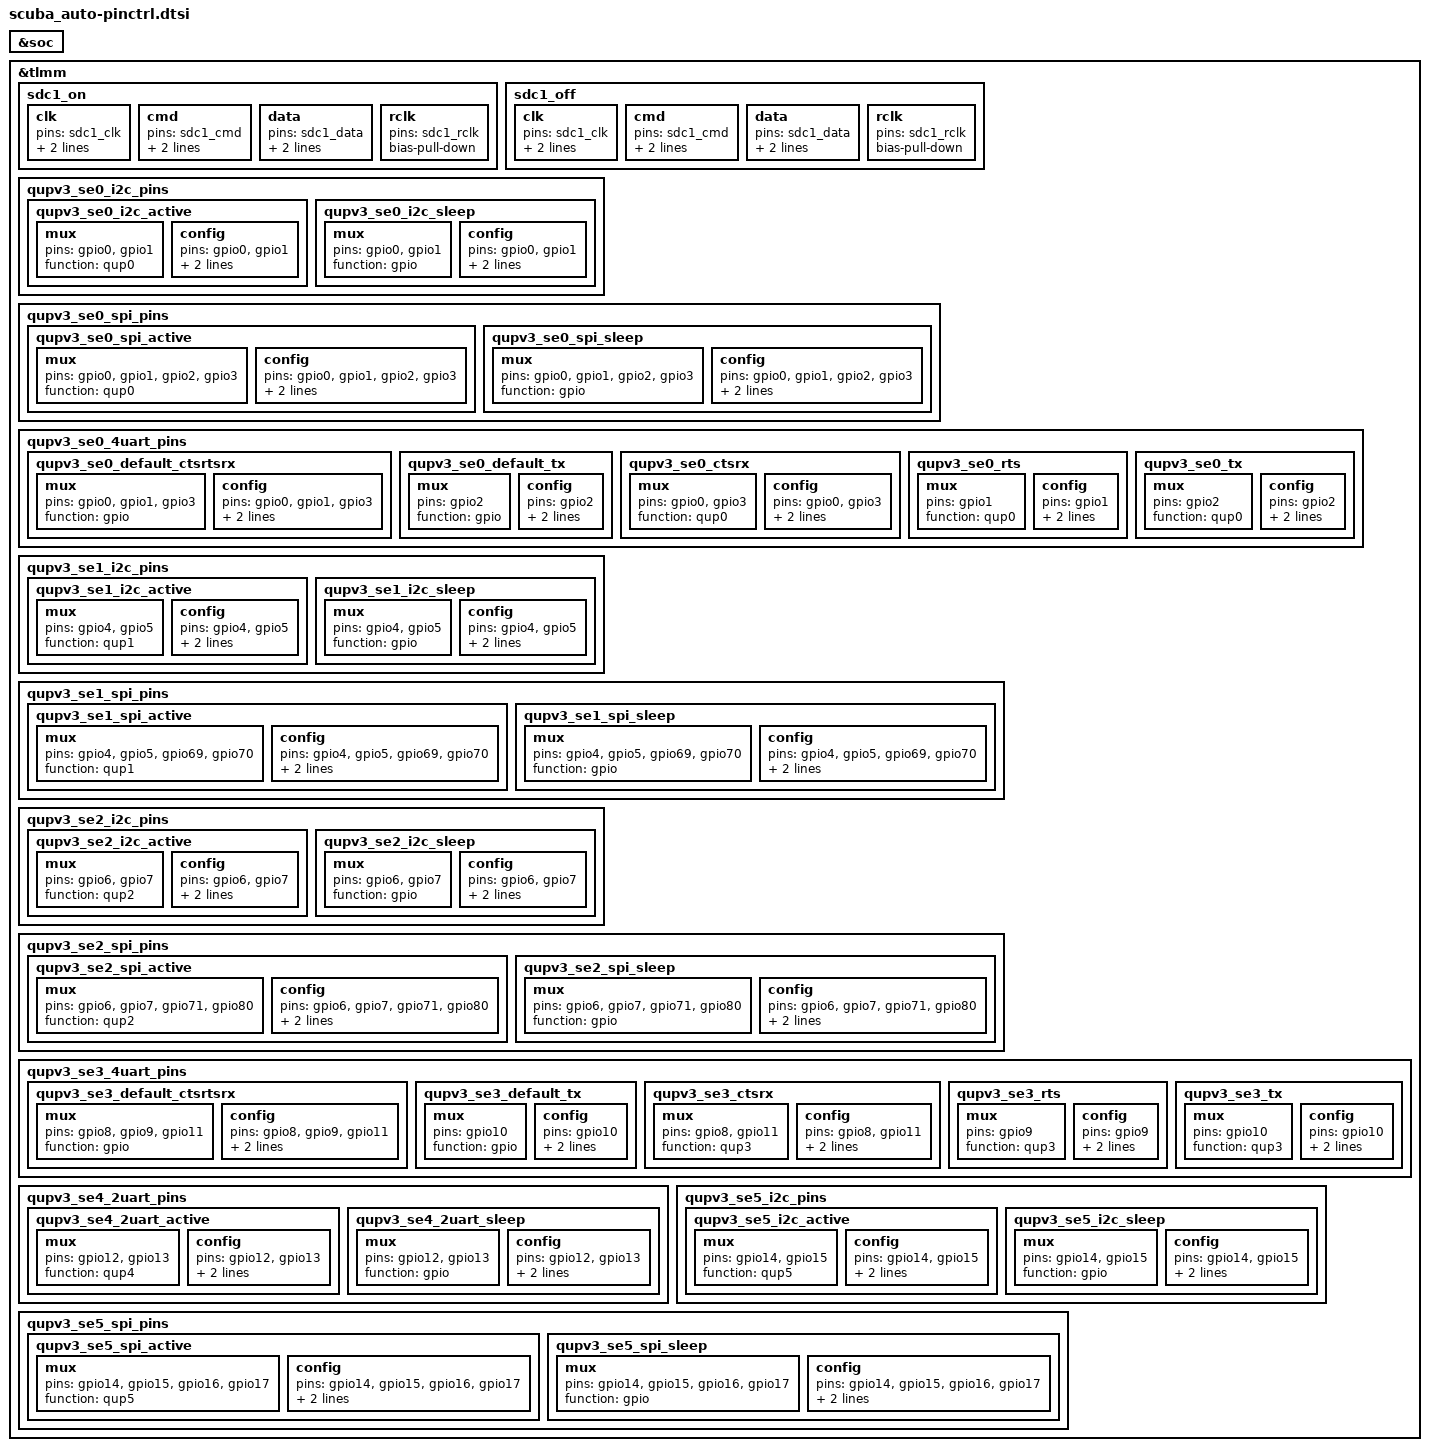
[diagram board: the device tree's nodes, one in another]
&soc { } ;
&tlmm {
	/* SDC pin type */
	sdc1_on: sdc1_on {
		clk {
			pins = "sdc1_clk";
			bias-disable;
			drive-strength = <16>;
		};

		cmd {
			pins = "sdc1_cmd";
			bias-pull-up;
			drive-strength = <10>;
		};

		data {
			pins = "sdc1_data";
			bias-pull-up;
			drive-strength = <10>;
		};

		rclk {
			pins = "sdc1_rclk";
			bias-pull-down;
		};
	};

	sdc1_off: sdc1_off {
		clk {
			pins = "sdc1_clk";
			bias-disable;
			drive-strength = <2>;
		};

		cmd {
			pins = "sdc1_cmd";
			bias-pull-up;
			drive-strength = <2>;
		};

		data {
			pins = "sdc1_data";
			bias-pull-up;
			drive-strength = <2>;
		};

		rclk {
			pins = "sdc1_rclk";
			bias-pull-down;
		};
	};

	qupv3_se0_i2c_pins: qupv3_se0_i2c_pins {
		qupv3_se0_i2c_active: qupv3_se0_i2c_active {
			mux {
				pins = "gpio0", "gpio1";
				function = "qup0";
			};

			config {
				pins = "gpio0", "gpio1";
				drive-strength = <2>;
				bias-pull-up;
			};
		};

		qupv3_se0_i2c_sleep: qupv3_se0_i2c_sleep {
			mux {
				pins = "gpio0", "gpio1";
				function = "gpio";
			};

			config {
				pins = "gpio0", "gpio1";
				drive-strength = <2>;
				bias-disable;
			};
		};
	};

	qupv3_se0_spi_pins: qupv3_se0_spi_pins {
		qupv3_se0_spi_active: qupv3_se0_spi_active {
			mux {
				pins = "gpio0", "gpio1",
						"gpio2", "gpio3";
				function = "qup0";
			};

			config {
				pins = "gpio0", "gpio1",
					"gpio2", "gpio3";
				drive-strength = <6>;
				bias-disable;
			};
		};

		qupv3_se0_spi_sleep: qupv3_se0_spi_sleep {
			mux {
				pins = "gpio0", "gpio1",
						"gpio2", "gpio3";
				function = "gpio";
			};

			config {
				pins = "gpio0", "gpio1",
						"gpio2", "gpio3";
				drive-strength = <6>;
				bias-disable;
			};
		};
	};

	qupv3_se0_4uart_pins: qupv3_se0_4uart_pins {
		qupv3_se0_default_ctsrtsrx:
			qupv3_se0_default_ctsrtsrx {
			mux {
				pins = "gpio0", "gpio1", "gpio3";
				function = "gpio";
			};

			config {
				pins = "gpio0", "gpio1", "gpio3";
				drive-strength = <2>;
				bias-pull-down;
			};
		};

		qupv3_se0_default_tx:
			qupv3_se0_default_tx {
			mux {
				pins = "gpio2";
				function = "gpio";
			};

			config {
				pins = "gpio2";
				drive-strength = <2>;
				bias-pull-up;
			};
		};

		qupv3_se0_ctsrx: qupv3_se0_ctsrx {
			mux {
				pins = "gpio0", "gpio3";
				function = "qup0";
			};

			config {
				pins = "gpio0", "gpio3";
				drive-strength = <2>;
				bias-disable;
			};
		};

		qupv3_se0_rts: qupv3_se0_rts {
			mux {
				pins = "gpio1";
				function = "qup0";
			};

			config {
				pins = "gpio1";
				drive-strength = <2>;
				bias-pull-down;
			};
		};

		qupv3_se0_tx: qupv3_se0_tx {
			mux {
				pins = "gpio2";
				function = "qup0";
			};

			config {
				pins = "gpio2";
				drive-strength = <2>;
				bias-pull-up;
			};
		};
	};

	qupv3_se1_i2c_pins: qupv3_se1_i2c_pins {
		qupv3_se1_i2c_active: qupv3_se1_i2c_active {
			mux {
				pins = "gpio4", "gpio5";
				function = "qup1";
			};

			config {
				pins = "gpio4", "gpio5";
				drive-strength = <2>;
				bias-pull-up;
			};
		};

		qupv3_se1_i2c_sleep: qupv3_se1_i2c_sleep {
			mux {
				pins = "gpio4", "gpio5";
				function = "gpio";
			};

			config {
				pins = "gpio4", "gpio5";
				drive-strength = <2>;
				bias-disable;
			};
		};
	};

	qupv3_se1_spi_pins: qupv3_se1_spi_pins {
		qupv3_se1_spi_active: qupv3_se1_spi_active {
			mux {
				pins = "gpio4", "gpio5",
						"gpio69", "gpio70";
				function = "qup1";
			};

			config {
				pins = "gpio4", "gpio5",
						"gpio69", "gpio70";
				drive-strength = <6>;
				bias-disable;
			};
		};

		qupv3_se1_spi_sleep: qupv3_se1_spi_sleep {
			mux {
				pins = "gpio4", "gpio5",
						"gpio69", "gpio70";
				function = "gpio";
			};

			config {
				pins = "gpio4", "gpio5",
						"gpio69", "gpio70";
				drive-strength = <6>;
				bias-disable;
			};
		};
	};

	qupv3_se2_i2c_pins: qupv3_se2_i2c_pins {
		qupv3_se2_i2c_active: qupv3_se2_i2c_active {
			mux {
				pins = "gpio6", "gpio7";
				function = "qup2";
			};

			config {
				pins = "gpio6", "gpio7";
				drive-strength = <2>;
				bias-pull-up;
			};
		};

		qupv3_se2_i2c_sleep: qupv3_se2_i2c_sleep {
			mux {
				pins = "gpio6", "gpio7";
				function = "gpio";
			};

			config {
				pins = "gpio6", "gpio7";
				drive-strength = <2>;
				bias-disable;
			};
		};
	};

	qupv3_se2_spi_pins: qupv3_se2_spi_pins {
		qupv3_se2_spi_active: qupv3_se2_spi_active {
			mux {
				pins = "gpio6", "gpio7",
						"gpio71", "gpio80";
				function = "qup2";
			};

			config {
				pins = "gpio6", "gpio7",
						"gpio71", "gpio80";
				drive-strength = <6>;
				bias-disable;
			};
		};

		qupv3_se2_spi_sleep: qupv3_se2_spi_sleep {
			mux {
				pins = "gpio6", "gpio7",
						"gpio71", "gpio80";
				function = "gpio";
			};

			config {
				pins = "gpio6", "gpio7",
						"gpio71", "gpio80";
				drive-strength = <6>;
				bias-disable;
			};
		};
	};

	qupv3_se3_4uart_pins: qupv3_se3_4uart_pins {
		qupv3_se3_default_ctsrtsrx:
			qupv3_se3_default_ctsrtsrx {
			mux {
				pins = "gpio8", "gpio9", "gpio11";
				function = "gpio";
			};

			config {
				pins = "gpio8", "gpio9", "gpio11";
				drive-strength = <2>;
				bias-pull-down;
			};
		};

		qupv3_se3_default_tx:
			qupv3_se3_default_tx {
			mux {
				pins = "gpio10";
				function = "gpio";
			};

			config {
				pins = "gpio10";
				drive-strength = <2>;
				bias-pull-up;
			};
		};

		qupv3_se3_ctsrx: qupv3_se3_ctsrx {
			mux {
				pins = "gpio8", "gpio11";
				function = "qup3";
			};

			config {
				pins = "gpio8", "gpio11";
				drive-strength = <2>;
				bias-disable;
			};
		};

		qupv3_se3_rts: qupv3_se3_rts {
			mux {
				pins = "gpio9";
				function = "qup3";
			};

			config {
				pins = "gpio9";
				drive-strength = <2>;
				bias-pull-down;
			};
		};

		qupv3_se3_tx: qupv3_se3_tx {
			mux {
				pins = "gpio10";
				function = "qup3";
			};

			config {
				pins = "gpio10";
				drive-strength = <2>;
				bias-pull-up;
			};
		};
	};

	qupv3_se4_2uart_pins: qupv3_se4_2uart_pins {
		qupv3_se4_2uart_active: qupv3_se4_2uart_active {
			mux {
				pins = "gpio12", "gpio13";
				function = "qup4";
			};

			config {
				pins = "gpio12", "gpio13";
				drive-strength = <2>;
				bias-disable;
			};
		};

		qupv3_se4_2uart_sleep: qupv3_se4_2uart_sleep {
			mux {
				pins = "gpio12", "gpio13";
				function = "gpio";
			};

			config {
				pins = "gpio12", "gpio13";
				drive-strength = <2>;
				bias-pull-down;
			};
		};
	};

	qupv3_se5_i2c_pins: qupv3_se5_i2c_pins {
		qupv3_se5_i2c_active: qupv3_se5_i2c_active {
			mux {
				pins = "gpio14", "gpio15";
				function = "qup5";
			};

			config {
				pins = "gpio14", "gpio15";
				drive-strength = <2>;
				bias-pull-up;
			};
		};

		qupv3_se5_i2c_sleep: qupv3_se5_i2c_sleep {
			mux {
				pins = "gpio14", "gpio15";
				function = "gpio";
			};

			config {
				pins = "gpio14", "gpio15";
				drive-strength = <2>;
				bias-disable;
			};
		};
	};

	qupv3_se5_spi_pins: qupv3_se5_spi_pins {
		qupv3_se5_spi_active: qupv3_se5_spi_active {
			mux {
				pins = "gpio14", "gpio15",
						"gpio16", "gpio17";
				function = "qup5";
			};

			config {
				pins = "gpio14", "gpio15",
						"gpio16", "gpio17";
				drive-strength = <6>;
				bias-disable;
			};
		};

		qupv3_se5_spi_sleep: qupv3_se5_spi_sleep {
			mux {
				pins = "gpio14", "gpio15",
						"gpio16", "gpio17";
				function = "gpio";
			};

			config {
				pins = "gpio14", "gpio15",
						"gpio16", "gpio17";
				drive-strength = <6>;
				bias-disable;
			};
		};
	};
};
